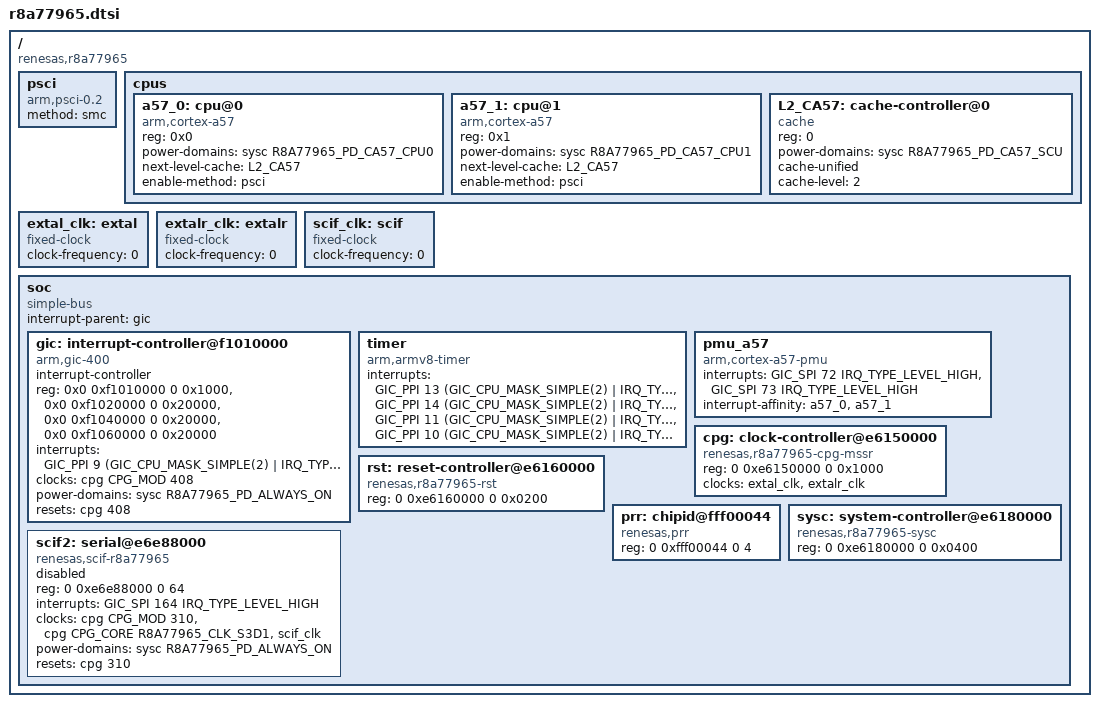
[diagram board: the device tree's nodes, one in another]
/*
 * Device Tree Source for the r8a77965 SoC
 *
 * Copyright (C) 2017 Renesas Electronics Corp.
 *
 * This file is licensed under the terms of the GNU General Public License
 * version 2.  This program is licensed "as is" without any warranty of any
 * kind, whether express or implied.
 */

#include <dt-bindings/clock/r8a77965-cpg-mssr.h>
#include <dt-bindings/interrupt-controller/arm-gic.h>
#include <dt-bindings/power/r8a77965-sysc.h>

/ {
	compatible = "renesas,r8a77965";
	#address-cells = <2>;
	#size-cells = <2>;

	psci {
		compatible = "arm,psci-0.2";
		method = "smc";
	};

	cpus {
		#address-cells = <1>;
		#size-cells = <0>;

		a57_0: cpu@0 {
			compatible = "arm,cortex-a57", "arm,armv8";
			reg = <0x0>;
			device_type = "cpu";
			power-domains = <&sysc R8A77965_PD_CA57_CPU0>;
			next-level-cache = <&L2_CA57>;
			enable-method = "psci";
		};

		a57_1: cpu@1 {
			compatible = "arm,cortex-a57","arm,armv8";
			reg = <0x1>;
			device_type = "cpu";
			power-domains = <&sysc R8A77965_PD_CA57_CPU1>;
			next-level-cache = <&L2_CA57>;
			enable-method = "psci";
		};

		L2_CA57: cache-controller@0 {
			compatible = "cache";
			reg = <0>;
			power-domains = <&sysc R8A77965_PD_CA57_SCU>;
			cache-unified;
			cache-level = <2>;
		};
	};

	extal_clk: extal {
		compatible = "fixed-clock";
		#clock-cells = <0>;
		/* This value must be overridden by the board */
		clock-frequency = <0>;
	};

	extalr_clk: extalr {
		compatible = "fixed-clock";
		#clock-cells = <0>;
		/* This value must be overridden by the board */
		clock-frequency = <0>;
	};

	/* External SCIF clock - to be overridden by boards that provide it */
	scif_clk: scif {
		compatible = "fixed-clock";
		#clock-cells = <0>;
		clock-frequency = <0>;
	};

	soc {
		compatible = "simple-bus";
		interrupt-parent = <&gic>;
		#address-cells = <2>;
		#size-cells = <2>;
		ranges;

		gic: interrupt-controller@f1010000 {
			compatible = "arm,gic-400";
			#interrupt-cells = <3>;
			#address-cells = <0>;
			interrupt-controller;
			reg = <0x0 0xf1010000 0 0x1000>,
			      <0x0 0xf1020000 0 0x20000>,
			      <0x0 0xf1040000 0 0x20000>,
			      <0x0 0xf1060000 0 0x20000>;
			interrupts = <GIC_PPI 9
					(GIC_CPU_MASK_SIMPLE(2) | IRQ_TYPE_LEVEL_HIGH)>;
			clocks = <&cpg CPG_MOD 408>;
			clock-names = "clk";
			power-domains = <&sysc R8A77965_PD_ALWAYS_ON>;
			resets = <&cpg 408>;
		};

		timer {
			compatible = "arm,armv8-timer";
			interrupts = <GIC_PPI 13
					(GIC_CPU_MASK_SIMPLE(2) | IRQ_TYPE_LEVEL_LOW)>,
				     <GIC_PPI 14
					(GIC_CPU_MASK_SIMPLE(2) | IRQ_TYPE_LEVEL_LOW)>,
				     <GIC_PPI 11
					(GIC_CPU_MASK_SIMPLE(2) | IRQ_TYPE_LEVEL_LOW)>,
				     <GIC_PPI 10
					(GIC_CPU_MASK_SIMPLE(2) | IRQ_TYPE_LEVEL_LOW)>;
		};

		pmu_a57 {
			compatible = "arm,cortex-a57-pmu";
			interrupts = <GIC_SPI 72 IRQ_TYPE_LEVEL_HIGH>,
				     <GIC_SPI 73 IRQ_TYPE_LEVEL_HIGH>;
			interrupt-affinity = <&a57_0>,
					     <&a57_1>;
		};

		cpg: clock-controller@e6150000 {
			compatible = "renesas,r8a77965-cpg-mssr";
			reg = <0 0xe6150000 0 0x1000>;
			clocks = <&extal_clk>, <&extalr_clk>;
			clock-names = "extal", "extalr";
			#clock-cells = <2>;
			#power-domain-cells = <0>;
			#reset-cells = <1>;
		};

		rst: reset-controller@e6160000 {
			compatible = "renesas,r8a77965-rst";
			reg = <0 0xe6160000 0 0x0200>;
		};

		prr: chipid@fff00044 {
			compatible = "renesas,prr";
			reg = <0 0xfff00044 0 4>;
		};

		sysc: system-controller@e6180000 {
			compatible = "renesas,r8a77965-sysc";
			reg = <0 0xe6180000 0 0x0400>;
			#power-domain-cells = <1>;
		};

		scif2: serial@e6e88000 {
			compatible = "renesas,scif-r8a77965",
				     "renesas,rcar-gen3-scif", "renesas,scif";
			reg = <0 0xe6e88000 0 64>;
			interrupts = <GIC_SPI 164 IRQ_TYPE_LEVEL_HIGH>;
			clocks = <&cpg CPG_MOD 310>,
				 <&cpg CPG_CORE R8A77965_CLK_S3D1>,
				 <&scif_clk>;
			clock-names = "fck", "brg_int", "scif_clk";
			power-domains = <&sysc R8A77965_PD_ALWAYS_ON>;
			resets = <&cpg 310>;
			status = "disabled";
		};
	};
};
